# STM32F100xB register map
File version: 1.0
Registers are 32-bit, read-write, reset 0x0 unless marked. A register's access mark holds for its fields unless they carry their own. Offsets are from the block's base; lines under a group give offsets from that group; [hi:lo] are bit positions; {n}, {i} and the like mark numbered series; 'fields as' and 'values as' point back to an identical list; <NAME> marks a mode.

## Memory map
0x1FFFF800 OB — Option Bytes Registers
0x40000000 TIM2 — TIM Timers
0x40000400 TIM3 — TIM Timers
0x40000800 TIM4 — TIM Timers
0x40001000 TIM6 — TIM Timers
0x40001400 TIM7 — TIM Timers
0x40002800 RTC — Real-Time Clock
0x40002C00 WWDG — Window WATCHDOG
0x40003000 IWDG — Independent WATCHDOG
0x40003800 SPI2 — Serial Peripheral Interface
0x40004400 USART2 — Universal Synchronous Asynchronous Receiver Transmitter
0x40004800 USART3 — Universal Synchronous Asynchronous Receiver Transmitter
0x40005400 I2C1 — Inter Integrated Circuit Interface
0x40005800 I2C2 — Inter Integrated Circuit Interface
0x40006C00 BKP — Backup Registers
0x40007000 PWR — Power Control
0x40007400 DAC — Digital to Analog Converter
0x40007400 DAC1 — Digital to Analog Converter
0x40007800 CEC — Consumer Electronics Control (CEC)
0x40010000 AFIO — Alternate Function I/O
0x40010400 EXTI — External Interrupt/Event Controller
0x40010800 GPIOA — General Purpose I/O
0x40010C00 GPIOB — General Purpose I/O
0x40011000 GPIOC — General Purpose I/O
0x40011400 GPIOD — General Purpose I/O
0x40011800 GPIOE — General Purpose I/O
0x40012400 ADC1 — Analog to Digital Converter
0x40012C00 TIM1 — TIM Timers
0x40013000 SPI1 — Serial Peripheral Interface
0x40013800 USART1 — Universal Synchronous Asynchronous Receiver Transmitter
0x40014000 TIM15 — TIM Timers
0x40014400 TIM16 — TIM Timers
0x40014800 TIM17 — TIM Timers
0x40020000 DMA1
0x40021000 RCC — Reset and Clock Control
0x40022000 FLASH — FLASH Registers
0x40023000 CRC — CRC calculation unit
0xE0042000 DBGMCU — Debug MCU

## Interrupts
0 WWDG — Window WatchDog Interrupt
3 RTC — RTC global Interrupt
4 FLASH — FLASH global Interrupt
5 RCC — RCC global Interrupt
6 EXTI0 (EXTI) — EXTI Line0 Interrupt
7 EXTI1 (EXTI) — EXTI Line1 Interrupt
8 EXTI2 (EXTI) — EXTI Line2 Interrupt
9 EXTI3 (EXTI) — EXTI Line3 Interrupt
10 EXTI4 (EXTI) — EXTI Line4 Interrupt
11 DMA1_Channel1 (DMA1) — DMA1 Channel 1 global Interrupt
12 DMA1_Channel2 (DMA1) — DMA1 Channel 2 global Interrupt
13 DMA1_Channel3 (DMA1) — DMA1 Channel 3 global Interrupt
14 DMA1_Channel4 (DMA1) — DMA1 Channel 4 global Interrupt
15 DMA1_Channel5 (DMA1) — DMA1 Channel 5 global Interrupt
16 DMA1_Channel6 (DMA1) — DMA1 Channel 6 global Interrupt
17 DMA1_Channel7 (DMA1) — DMA1 Channel 7 global Interrupt
18 ADC1 — ADC1 global Interrupt
23 EXTI9_5 (EXTI) — External Line[9:5] Interrupts
24 TIM1_BRK_TIM15 (TIM15) — TIM1 Break and TIM15 Interrupts
25 TIM1_UP_TIM16 (TIM16) — TIM1 Update and TIM16 Interrupts
26 TIM1_TRG_COM_TIM17 (TIM17) — TIM1 Trigger and Commutation and TIM17 Interrupt
27 TIM1_CC (TIM1) — TIM1 Capture Compare Interrupt
28 TIM2 — TIM2 global Interrupt
29 TIM3 — TIM3 global Interrupt
30 TIM4 — TIM4 global Interrupt
31 I2C1_EV (I2C1) — I2C1 Event Interrupt
32 I2C1_ER (I2C1) — I2C1 Error Interrupt
33 I2C2_EV (I2C2) — I2C2 Event Interrupt
34 I2C2_ER (I2C2) — I2C2 Error Interrupt
35 SPI1 — SPI1 global Interrupt
36 SPI2 — SPI2 global Interrupt
37 USART1 — USART1 global Interrupt
38 USART2 — USART2 global Interrupt
39 USART3 — USART3 global Interrupt
40 EXTI15_10 (EXTI) — External Line[15:10] Interrupts
41 RTC_Alarm (RTC) — RTC Alarm through EXTI Line Interrupt
42 CEC — HDMI-CEC Interrupt
54 TIM6_DAC (TIM6, DAC) — TIM6 and DAC underrun Interrupt
55 TIM7 — TIM7 global Interrupt

## OB — Option Bytes Registers
Base 0x1FFFF800
0x00 RDP 16-bit
0x02 USER 16-bit
0x04 Data0 16-bit
0x06 Data1 16-bit
{0x8+2i} WRP{i} 16-bit (i=0..3)

## TIM6 — TIM Timers
Base 0x40001000
Same registers: TIM7 0x40001400
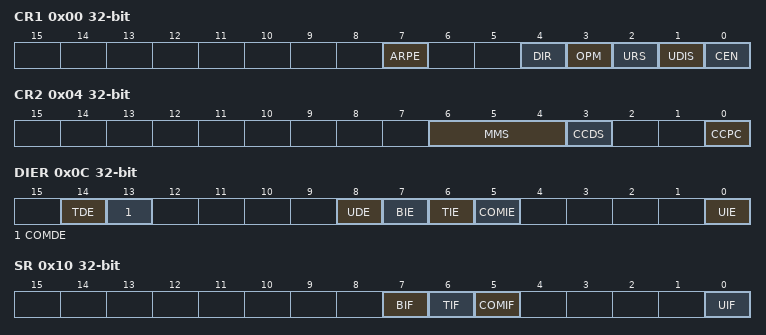
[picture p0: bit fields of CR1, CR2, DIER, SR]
0x00 CR1 — TIM control register 1
  [7] ARPE — Auto-reload preload enable
  [4] DIR — Direction
    0=UP (Timer counter counts up); 1=DOWN (Timer counter counts down)
  [3] OPM — One pulse mode
    1=SINGLE (Counter stops counting at the next update event); 0=REPETITIVE (Counter is not stopped at update event)
  [2] URS — Update request source
    0=REGULAR (Counter overflow/underflow, Setting the UG bit or Update generation through the slave mode controller generates an update request); 1=COUNTER (Only counter overflow/underflow generates an update request)
  [1] UDIS — Update disable
  [0] CEN — Counter enable
0x04 CR2 — TIM control register 2
  [6:4] MMS — MMS[2:0] bits (Master Mode Selection)
    0=RESET (UG bit from the TIMx_EGR register is used as trigger output); 1=ENABLE (Counter Enable signal (CNT_EN) is used as trigger output); 2=UPDATE (Update event is used as trigger output); 3=CC1IF (CC1 capture or a compare match is used as trigger output); {v}=OC{v-3}REF (OC{v-3}REF signal is used as trigger output) (v=4..7)
  [3] CCDS — Capture/Compare DMA Selection
    0=CC (CCx DMA request sent when CCx event occurs); 1=UPDATE (CCx DMA requests sent when update event occurs)
  [0] CCPC — Capture/Compare Preloaded Control
0x0C DIER — TIM DMA/interrupt enable register
  [14] TDE — Trigger DMA request enable
  [13] COMDE — COM DMA request enable
  [8] UDE — Update DMA request enable
  [7] BIE — Break interrupt enable
  [6] TIE — Trigger interrupt enable
  [5] COMIE — COM interrupt enable
  [0] UIE — Update interrupt enable
0x10 SR — TIM status register
  [7] BIF — Break interrupt Flag
  [6] TIF — Trigger interrupt Flag
  [5] COMIF — COM interrupt Flag
  [0] UIF — Update interrupt Flag
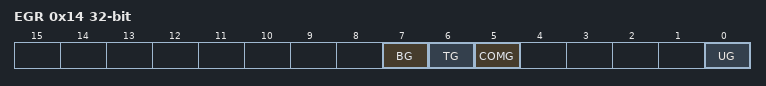
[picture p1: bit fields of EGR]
0x14 EGR — TIM event generation register
  [7] BG — Break Generation
  [6] TG — Trigger Generation
  [5] COMG — Capture/Compare Control Update Generation
  [0] UG — Update Generation
0x24 CNT — TIM counter register
  [31:0] CNT — Counter Value
0x28 PSC — TIM prescaler register
  [15:0] PSC — Prescaler Value
0x2C ARR — TIM auto-reload register
  [31:0] ARR — actual auto-reload Value
0x4C DMAR — TIM DMA address for full transfer register
  [15:0] DMAB — DMA register for burst accesses
0x50 OR — TIM option register
